VERSION "ev-fleet thermal 1.0"

NS_ :

BS_:

BU_: ThermalMgr DCDC OBC VCU BMS

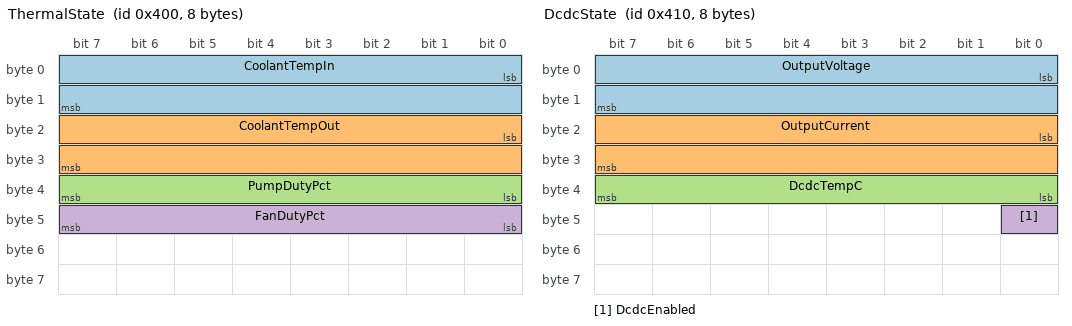
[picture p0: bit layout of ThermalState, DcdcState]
BO_ 1024 ThermalState: 8 ThermalMgr
 SG_ CoolantTempIn : 0|16@1- (0.1,-40) [-40|6513.5] "degC" VCU,BMS
 SG_ CoolantTempOut : 16|16@1- (0.1,-40) [-40|6513.5] "degC" VCU,BMS
 SG_ PumpDutyPct : 32|8@1+ (0.5,0) [0|127.5] "%" VCU
 SG_ FanDutyPct : 40|8@1+ (0.5,0) [0|127.5] "%" VCU

BO_ 1040 DcdcState: 8 DCDC
 SG_ OutputVoltage : 0|16@1+ (0.01,0) [0|655.35] "V" VCU
 SG_ OutputCurrent : 16|16@1- (0.1,0) [-3276.8|3276.7] "A" VCU
 SG_ DcdcTempC : 32|8@1- (1,-40) [-40|87] "degC" VCU
 SG_ DcdcEnabled : 40|1@1+ (1,0) [0|1] "" VCU

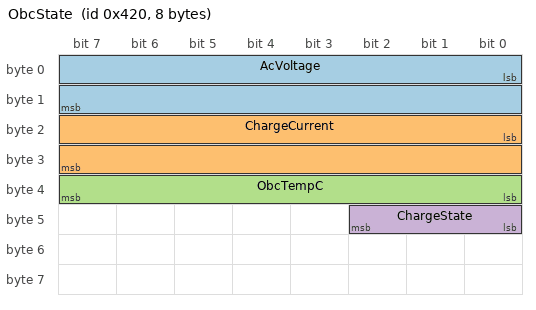
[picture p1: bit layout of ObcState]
BO_ 1056 ObcState: 8 OBC
 SG_ AcVoltage : 0|16@1+ (0.1,0) [0|6553.5] "V" VCU,BMS
 SG_ ChargeCurrent : 16|16@1+ (0.1,0) [0|6553.5] "A" VCU,BMS
 SG_ ObcTempC : 32|8@1- (1,-40) [-40|87] "degC" VCU
 SG_ ChargeState : 40|3@1+ (1,0) [0|7] "" VCU,BMS

BO_ 1072 ThermalZoneReport: 8 ThermalMgr
 SG_ ZoneIndex M : 0|4@1+ (1,0) [0|3] "" VCU
 SG_ Zone1TempC m0 : 8|8@1- (1,-40) [-40|87] "degC" VCU
 SG_ Zone1FanPct m0 : 16|8@1+ (0.5,0) [0|100] "%" VCU
 SG_ Zone1ValveOpen m0 : 24|1@1+ (1,0) [0|1] "" VCU
 SG_ Zone2TempC m1 : 8|8@1- (1,-40) [-40|87] "degC" VCU
 SG_ Zone2FanPct m1 : 16|8@1+ (0.5,0) [0|100] "%" VCU
 SG_ Zone2ValveOpen m1 : 24|1@1+ (1,0) [0|1] "" VCU
 SG_ Zone3TempC m2 : 8|8@1- (1,-40) [-40|87] "degC" VCU
 SG_ Zone3FanPct m2 : 16|8@1+ (0.5,0) [0|100] "%" VCU
 SG_ Zone3ValveOpen m2 : 24|1@1+ (1,0) [0|1] "" VCU
 SG_ Zone4TempC m3 : 8|8@1- (1,-40) [-40|87] "degC" VCU
 SG_ Zone4FanPct m3 : 16|8@1+ (0.5,0) [0|100] "%" VCU
 SG_ Zone4ValveOpen m3 : 24|1@1+ (1,0) [0|1] "" VCU

CM_ BO_ 1024 "Coolant loop state, 100 ms cadence on the battery bus, standard 11-bit ID. Read by the VCU and BMS.";
CM_ BO_ 1040 "DC-DC converter state (HV to 12 V), 100 ms cadence.";
CM_ BO_ 1056 "On-board charger state, 200 ms cadence. The BMS gates charging on these.";
CM_ SG_ 1056 ChargeState "0=Idle 1=Precharge 2=Charging 3=Complete 4=Fault.";
CM_ BO_ 1072 "Per-zone thermal bundle, 200 ms cadence: ZoneIndex cycles the four cabin/pack zones, each frame carrying that zone's temperature, fan duty, and valve state. The selector is an index (no VAL_ table), so its arms read m0-m3.";
CM_ SG_ 1072 ZoneIndex "Multiplex selector -- which zone this frame carries.";

BA_DEF_ BO_ "GenMsgCycleTime" INT 0 100000;
BA_DEF_DEF_ "GenMsgCycleTime" 0;
BA_ "GenMsgCycleTime" BO_ 1024 100;
BA_ "GenMsgCycleTime" BO_ 1040 100;
BA_ "GenMsgCycleTime" BO_ 1056 200;
BA_ "GenMsgCycleTime" BO_ 1072 200;

VAL_ 1056 ChargeState 0 "Idle" 1 "Precharge" 2 "Charging" 3 "Complete" 4 "Fault";
